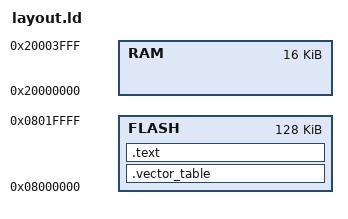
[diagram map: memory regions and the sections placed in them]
MEMORY
{
  FLASH : ORIGIN = 0x08000000, LENGTH = 128K
  RAM   : ORIGIN = 0x20000000, LENGTH = 16K
}

SECTIONS
{
  .vector_table ORIGIN(FLASH) :
  {
    LONG(ORIGIN(RAM) + LENGTH(RAM))
    KEEP(*(.reset))
    KEEP(*(.exceptions))
    KEEP(*(.irqs))
  } > FLASH

  .text :
  {
    *(.text*)
  } > FLASH

  /DISCARD/ :
  {
    *(.ARM.exidx*)
    *(.note.gnu.build-id*)
  }
}
